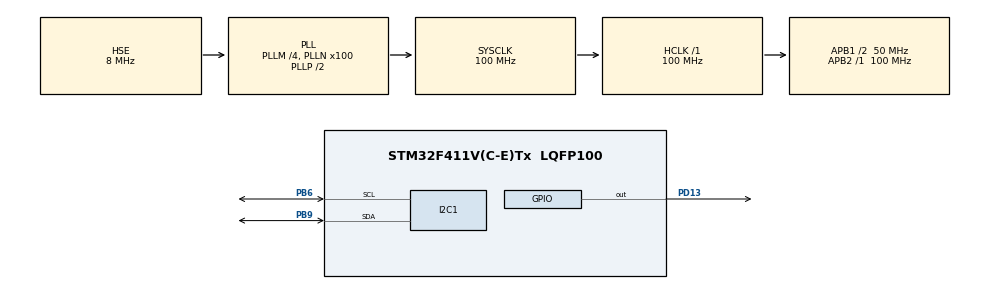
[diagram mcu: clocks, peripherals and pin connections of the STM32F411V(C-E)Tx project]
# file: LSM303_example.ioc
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Mcu.Family=STM32F4
Mcu.Name=STM32F411V(C-E)Tx
Mcu.Package=LQFP100
NVIC.PriorityGroup=NVIC_PRIORITYGROUP_4
NVIC.TIM2_IRQn=true\:0\:0\:false\:false\:true\:true\:true
PB6.Mode=I2C
PB6.Signal=I2C1_SCL
PB9.Mode=I2C
PB9.Signal=I2C1_SDA
PD13.Signal=GPIO_Output
PH0\ -\ OSC_IN.Mode=HSE-External-Oscillator
PH0\ -\ OSC_IN.Signal=RCC_OSC_IN
PH1\ -\ OSC_OUT.Mode=HSE-External-Oscillator
PH1\ -\ OSC_OUT.Signal=RCC_OSC_OUT
ProjectManager.HeapSize=0x200
ProjectManager.StackSize=0x400
ProjectManager.TargetToolchain=STM32CubeIDE
RCC.48MHZClocksFreq_Value=50000000
RCC.AHBFreq_Value=100000000
RCC.APB1CLKDivider=RCC_HCLK_DIV2
RCC.APB1Freq_Value=50000000
RCC.APB1TimFreq_Value=100000000
RCC.APB2Freq_Value=100000000
RCC.APB2TimFreq_Value=100000000
RCC.CortexFreq_Value=100000000
RCC.HCLKFreq_Value=100000000
RCC.HSE_VALUE=8000000
RCC.HSI_VALUE=16000000
RCC.LSE_VALUE=32768
RCC.PLLM=4
RCC.PLLN=100
RCC.PLLSourceVirtual=RCC_PLLSOURCE_HSE
RCC.SYSCLKFreq_VALUE=100000000
RCC.SYSCLKSource=RCC_SYSCLKSOURCE_PLLCLK
RCC.VCOOutputFreq_Value=200000000
TIM2.AutoReloadPreload=TIM_AUTORELOAD_PRELOAD_ENABLE
TIM2.Period=1000
TIM2.Prescaler=1000
VP_TIM2_VS_ClockSourceINT.Mode=Internal
board=custom

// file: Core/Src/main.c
/* USER CODE BEGIN Header */
/**
  ******************************************************************************
  * @file           : main.c
  * @brief          : Main program body
  ******************************************************************************
  * @attention
  *
  * <h2><center>&copy; Copyright (c) 2021 STMicroelectronics.
  * All rights reserved.</center></h2>
  *
  * This software component is licensed by ST under BSD 3-Clause license,
  * the "License"; You may not use this file except in compliance with the
  * License. You may obtain a copy of the License at:
  *                        opensource.org/licenses/BSD-3-Clause
  *
  ******************************************************************************
  */
/* USER CODE END Header */
#include "main.h"

/* USER CODE BEGIN Includes */
#include "stdbool.h"
/* USER CODE END Includes */

/* USER CODE BEGIN PD */
#define I2C1_SCL_Pin GPIO_PIN_6
#define I2C1_SCL_GPIO_Port GPIOB
#define I2C1_SDA_Pin GPIO_PIN_9
#define I2C1_SDA_GPIO_Port GPIOB
/* USER CODE END PD */

I2C_HandleTypeDef hi2c1;

TIM_HandleTypeDef htim2;

/* USER CODE BEGIN PV */
uint32_t tick = 1234;
HAL_StatusTypeDef status1;
HAL_StatusTypeDef status2;
unsigned char adr;
uint8_t ctrl_reg1_a;
uint8_t ctrl_reg2_a;
uint8_t ctrl_reg3_a;
uint8_t ctrl_reg4_a;
uint8_t ctrl_reg5_a;
uint8_t ctrl_reg6_a;
uint8_t dataXL = 255;
uint8_t dataXH = 255;
uint8_t dataYL = 255;
uint8_t dataYH = 255;
uint8_t dataZL = 255;
uint8_t dataZH = 255;
uint8_t sensorAddr = 0;
uint8_t memAddr = 0;
/* USER CODE END PV */

void SystemClock_Config(void);
static void MX_GPIO_Init(void);
static void MX_TIM2_Init(void);
static void MX_I2C1_Init(void);

/* USER CODE BEGIN 0 */
static bool wait_for_gpio_state_timeout(GPIO_TypeDef *port, uint16_t pin, GPIO_PinState state, uint32_t timeout)
 {
    uint32_t Tickstart = HAL_GetTick();
    bool ret = true;
    /* Wait until flag is set */
    for(;(state != HAL_GPIO_ReadPin(port, pin)) && (true == ret);)
    {
        /* Check for the timeout */
        if (timeout != HAL_MAX_DELAY)
        {
            if ((timeout == 0U) || ((HAL_GetTick() - Tickstart) > timeout))
            {
                ret = false;
            }
            else
            {
            }
        }
        asm("nop");
    }
    return ret;
}

static void I2C_ClearBusyFlagErratum(I2C_HandleTypeDef* handle, uint32_t timeout)
{
    GPIO_InitTypeDef GPIO_InitStructure;

    // 1. Clear PE bit.
    CLEAR_BIT(handle->Instance->CR1, I2C_CR1_PE);

    //  2. Configure the SCL and SDA I/Os as General Purpose Output Open-Drain, High level (Write 1 to GPIOx_ODR).
    HAL_I2C_DeInit(handle);

    GPIO_InitStructure.Mode = GPIO_MODE_OUTPUT_OD;
    GPIO_InitStructure.Pull = GPIO_NOPULL;

    GPIO_InitStructure.Pin = I2C1_SCL_Pin;
    HAL_GPIO_Init(GPIOB, &GPIO_InitStructure);

    GPIO_InitStructure.Pin = I2C1_SDA_Pin;
    HAL_GPIO_Init(I2C1_SDA_GPIO_Port, &GPIO_InitStructure);

    // 3. Check SCL and SDA High level in GPIOx_IDR.
    HAL_GPIO_WritePin(I2C1_SDA_GPIO_Port, I2C1_SDA_Pin, GPIO_PIN_SET);
    HAL_GPIO_WritePin(I2C1_SCL_GPIO_Port, I2C1_SCL_Pin, GPIO_PIN_SET);

    wait_for_gpio_state_timeout(I2C1_SCL_GPIO_Port, I2C1_SCL_Pin, GPIO_PIN_SET, timeout);
    wait_for_gpio_state_timeout(I2C1_SDA_GPIO_Port, I2C1_SDA_Pin, GPIO_PIN_SET, timeout);

    // 4. Configure the SDA I/O as General Purpose Output Open-Drain, Low level (Write 0 to GPIOx_ODR).
    HAL_GPIO_WritePin(I2C1_SDA_GPIO_Port, I2C1_SDA_Pin, GPIO_PIN_RESET);

    // 5. Check SDA Low level in GPIOx_IDR.
    wait_for_gpio_state_timeout(I2C1_SDA_GPIO_Port, I2C1_SDA_Pin, GPIO_PIN_RESET, timeout);

    // 6. Configure the SCL I/O as General Purpose Output Open-Drain, Low level (Write 0 to GPIOx_ODR).
    HAL_GPIO_WritePin(I2C1_SCL_GPIO_Port, I2C1_SCL_Pin, GPIO_PIN_RESET);

    // 7. Check SCL Low level in GPIOx_IDR.
    wait_for_gpio_state_timeout(I2C1_SCL_GPIO_Port, I2C1_SCL_Pin, GPIO_PIN_RESET, timeout);

    // 8. Configure the SCL I/O as General Purpose Output Open-Drain, High level (Write 1 to GPIOx_ODR).
    HAL_GPIO_WritePin(I2C1_SCL_GPIO_Port, I2C1_SCL_Pin, GPIO_PIN_SET);

    // 9. Check SCL High level in GPIOx_IDR.
    wait_for_gpio_state_timeout(I2C1_SCL_GPIO_Port, I2C1_SCL_Pin, GPIO_PIN_SET, timeout);

    // 10. Configure the SDA I/O as General Purpose Output Open-Drain , High level (Write 1 to GPIOx_ODR).
    HAL_GPIO_WritePin(I2C1_SDA_GPIO_Port, I2C1_SDA_Pin, GPIO_PIN_SET);

    // 11. Check SDA High level in GPIOx_IDR.
    wait_for_gpio_state_timeout(I2C1_SDA_GPIO_Port, I2C1_SDA_Pin, GPIO_PIN_SET, timeout);

    // 12. Configure the SCL and SDA I/Os as Alternate function Open-Drain.
    GPIO_InitStructure.Mode = GPIO_MODE_AF_OD;
    GPIO_InitStructure.Alternate = GPIO_AF4_I2C1;

    GPIO_InitStructure.Pin = I2C1_SCL_Pin;
    HAL_GPIO_Init(I2C1_SCL_GPIO_Port, &GPIO_InitStructure);

    GPIO_InitStructure.Pin = I2C1_SDA_Pin;
    HAL_GPIO_Init(I2C1_SDA_GPIO_Port, &GPIO_InitStructure);

    // 13. Set SWRST bit in I2Cx_CR1 register.
    SET_BIT(handle->Instance->CR1, I2C_CR1_SWRST);
    asm("nop");

    /* 14. Clear SWRST bit in I2Cx_CR1 register. */
    CLEAR_BIT(handle->Instance->CR1, I2C_CR1_SWRST);
    asm("nop");

    /* 15. Enable the I2C peripheral by setting the PE bit in I2Cx_CR1 register */
    SET_BIT(handle->Instance->CR1, I2C_CR1_PE);
    asm("nop");

    // Call initialization function.
    HAL_I2C_Init(handle);
}
/* USER CODE END 0 */

int main(void)
{

  /* MCU Configuration--------------------------------------------------------*/

  /* Reset of all peripherals, Initializes the Flash interface and the Systick. */
  HAL_Init();

  /* Configure the system clock */
  SystemClock_Config();

  /* Initialize all configured peripherals */
  MX_GPIO_Init();
  MX_TIM2_Init();
  MX_I2C1_Init();
  /* USER CODE BEGIN 2 */
  HAL_TIM_Base_Start_IT(&htim2);

  sensorAddr = 0x32;

  /* USER CODE END 2 */

  /* Infinite loop */
  /* USER CODE BEGIN WHILE */
  while (1)
  {

	  status1 = HAL_I2C_IsDeviceReady(&hi2c1,0X32,1000,1000);
	  if(status1 == HAL_BUSY){
		  I2C_ClearBusyFlagErratum(&hi2c1, 1000);
	  }

	  uint8_t data;
	  memAddr=0x0F;
	  HAL_I2C_Mem_Read(&hi2c1,0X32,memAddr,1,&data,1,100);

	  //check sensor documentation for control registers setup
	  data = 0b10010111;
	  memAddr = 0x20;
	  status2 = HAL_I2C_Mem_Write(&hi2c1,0X32,memAddr,1,&data,1,1000);

	  /*//sensor control registers status:
	  memAddr = 0x20;
	  status2 = HAL_I2C_Mem_Read(&hi2c1,0X32,memAddr,1,&ctrl_reg1_a,1,1000);
	  memAddr++;
	  status2 = HAL_I2C_Mem_Read(&hi2c1,0X32,memAddr,1,&ctrl_reg2_a,1,1000);
	  memAddr++;
	  status2 = HAL_I2C_Mem_Read(&hi2c1,0X32,memAddr,1,&ctrl_reg3_a,1,1000);
	  memAddr++;
	  status2 = HAL_I2C_Mem_Read(&hi2c1,0X32,memAddr,1,&ctrl_reg4_a,1,1000);
	  memAddr++;
	  status2 = HAL_I2C_Mem_Read(&hi2c1,0X32,memAddr,1,&ctrl_reg5_a,1,1000);
	  memAddr++;
	  status2 = HAL_I2C_Mem_Read(&hi2c1,0X32,memAddr,1,&ctrl_reg6_a,1,1000);
	  */

	  memAddr = 0x28;
	  status2 = HAL_I2C_Mem_Read(&hi2c1,0X32,memAddr,1,&dataXL,1,1000);
	  memAddr++;
	  status2 = HAL_I2C_Mem_Read(&hi2c1,0X32,memAddr,1,&dataXH,1,1000);
	  memAddr++;
	  status2 = HAL_I2C_Mem_Read(&hi2c1,0X32,memAddr,1,&dataYL,1,1000);
	  memAddr++;
	  status2 = HAL_I2C_Mem_Read(&hi2c1,0X32,memAddr,1,&dataYH,1,1000);
	  memAddr++;
	  status2 = HAL_I2C_Mem_Read(&hi2c1,0X32,memAddr,1,&dataZL,1,1000);
	  memAddr++;
	  status2 = HAL_I2C_Mem_Read(&hi2c1,0X32,memAddr,1,&dataZH,1,1000);

	  // the acceleration data is expressed as 2's complement, lef-justified
	  // int16_t already stores data in 2's complement format, so we can use it to form the final value
	  // the following code only applies for 10 bit resolution, where the MSB is the sign
	  int16_t x = dataXH;
	  x<<=8;
	  x|= dataXL;
	  x>>=6; // or 8 for 8 bit resolution, or 4 for 12 bit resolution
	  float xAcc;
	  xAcc=(float)x/256; // only applies for +-2g acc mode

	  int16_t y = dataYH;
	  y<<=8;
	  y|= dataYL;
	  y>>=6;
	  float yAcc;
	  yAcc=(float)y/256; // only applies for +-2g acc mode

	  int16_t z = dataZH;
	  z<<=8;
	  z|= dataZL;
	  z>>=6;
	  float zAcc;
	  zAcc=(float)z/256; // only applies for +-2g acc mode

    /* USER CODE END WHILE */

  }
}

void SystemClock_Config(void)
{
  RCC_OscInitTypeDef RCC_OscInitStruct = {0};
  RCC_ClkInitTypeDef RCC_ClkInitStruct = {0};

  /** Configure the main internal regulator output voltage
  */
  __HAL_RCC_PWR_CLK_ENABLE();
  __HAL_PWR_VOLTAGESCALING_CONFIG(PWR_REGULATOR_VOLTAGE_SCALE1);
  /** Initializes the RCC Oscillators according to the specified parameters
  * in the RCC_OscInitTypeDef structure.
  */
  RCC_OscInitStruct.OscillatorType = RCC_OSCILLATORTYPE_HSE;
  RCC_OscInitStruct.HSEState = RCC_HSE_ON;
  RCC_OscInitStruct.PLL.PLLState = RCC_PLL_ON;
  RCC_OscInitStruct.PLL.PLLSource = RCC_PLLSOURCE_HSE;
  RCC_OscInitStruct.PLL.PLLM = 4;
  RCC_OscInitStruct.PLL.PLLN = 100;
  RCC_OscInitStruct.PLL.PLLP = RCC_PLLP_DIV2;
  RCC_OscInitStruct.PLL.PLLQ = 4;
  if (HAL_RCC_OscConfig(&RCC_OscInitStruct) != HAL_OK)
  {
    Error_Handler();
  }
  /** Initializes the CPU, AHB and APB buses clocks
  */
  RCC_ClkInitStruct.ClockType = RCC_CLOCKTYPE_HCLK|RCC_CLOCKTYPE_SYSCLK
                              |RCC_CLOCKTYPE_PCLK1|RCC_CLOCKTYPE_PCLK2;
  RCC_ClkInitStruct.SYSCLKSource = RCC_SYSCLKSOURCE_PLLCLK;
  RCC_ClkInitStruct.AHBCLKDivider = RCC_SYSCLK_DIV1;
  RCC_ClkInitStruct.APB1CLKDivider = RCC_HCLK_DIV2;
  RCC_ClkInitStruct.APB2CLKDivider = RCC_HCLK_DIV1;

  if (HAL_RCC_ClockConfig(&RCC_ClkInitStruct, FLASH_LATENCY_3) != HAL_OK)
  {
    Error_Handler();
  }
}

static void MX_I2C1_Init(void)
{

  hi2c1.Instance = I2C1;
  hi2c1.Init.ClockSpeed = 100000;
  hi2c1.Init.DutyCycle = I2C_DUTYCYCLE_2;
  hi2c1.Init.OwnAddress1 = 0;
  hi2c1.Init.AddressingMode = I2C_ADDRESSINGMODE_7BIT;
  hi2c1.Init.DualAddressMode = I2C_DUALADDRESS_DISABLE;
  hi2c1.Init.OwnAddress2 = 0;
  hi2c1.Init.GeneralCallMode = I2C_GENERALCALL_DISABLE;
  hi2c1.Init.NoStretchMode = I2C_NOSTRETCH_DISABLE;
  if (HAL_I2C_Init(&hi2c1) != HAL_OK)
  {
    Error_Handler();
  }

}

static void MX_TIM2_Init(void)
{

  TIM_ClockConfigTypeDef sClockSourceConfig = {0};
  TIM_MasterConfigTypeDef sMasterConfig = {0};

  htim2.Instance = TIM2;
  htim2.Init.Prescaler = 1000;
  htim2.Init.CounterMode = TIM_COUNTERMODE_UP;
  htim2.Init.Period = 1000;
  htim2.Init.ClockDivision = TIM_CLOCKDIVISION_DIV1;
  htim2.Init.AutoReloadPreload = TIM_AUTORELOAD_PRELOAD_ENABLE;
  if (HAL_TIM_Base_Init(&htim2) != HAL_OK)
  {
    Error_Handler();
  }
  sClockSourceConfig.ClockSource = TIM_CLOCKSOURCE_INTERNAL;
  if (HAL_TIM_ConfigClockSource(&htim2, &sClockSourceConfig) != HAL_OK)
  {
    Error_Handler();
  }
  sMasterConfig.MasterOutputTrigger = TIM_TRGO_RESET;
  sMasterConfig.MasterSlaveMode = TIM_MASTERSLAVEMODE_DISABLE;
  if (HAL_TIMEx_MasterConfigSynchronization(&htim2, &sMasterConfig) != HAL_OK)
  {
    Error_Handler();
  }

}

static void MX_GPIO_Init(void)
{
  GPIO_InitTypeDef GPIO_InitStruct = {0};

  /* GPIO Ports Clock Enable */
  __HAL_RCC_GPIOH_CLK_ENABLE();
  __HAL_RCC_GPIOD_CLK_ENABLE();
  __HAL_RCC_GPIOB_CLK_ENABLE();

  /*Configure GPIO pin Output Level */
  HAL_GPIO_WritePin(GPIOD, GPIO_PIN_13, GPIO_PIN_RESET);

  /*Configure GPIO pin : PD13 */
  GPIO_InitStruct.Pin = GPIO_PIN_13;
  GPIO_InitStruct.Mode = GPIO_MODE_OUTPUT_PP;
  GPIO_InitStruct.Pull = GPIO_NOPULL;
  GPIO_InitStruct.Speed = GPIO_SPEED_FREQ_LOW;
  HAL_GPIO_Init(GPIOD, &GPIO_InitStruct);

}

void Error_Handler(void)
{
  __disable_irq();
  while (1)
  {
  }
}

/************************ (C) COPYRIGHT STMicroelectronics *****END OF FILE****/
